# AltaRiscv register map
File version: 1.0
Registers are 32-bit, read-write, reset 0x0 unless marked. A register's access mark holds for its fields unless they carry their own. Offsets are from the block's base; lines under a group give offsets from that group; [hi:lo] are bit positions; {n}, {i} and the like mark numbered series; 'fields as' and 'values as' point back to an identical list; <NAME> marks a mode.

## Memory map
0x02000000 CLINT size 0x10000 — Core local interrupt controller
0x03000000 SYS size 0x1000 — System control
0x0C000000 PLIC size 0x400000 — Platform local interrupt controller
0x40000000 RTC size 0x80 — Real time clock
0x40001000 FLASH size 0x1000 — Flash controller
0x40010000 FCB0 size 0x1000 — FCB registers
0x40011000 WATCHDOG0 size 0x1000 — WATCHDOG registers
0x40012000 SPI0 size 0x100 — SPI registers
0x40013000 SPI1 size 0x100
0x40014000 GPIO0 size 0x1000 — GPIO registers
{0x40014000+0x1000*n} GPIO{n} size 0x1000 (n=1..9)
0x4001E000 TIMER0 size 0x1000 — TIMER registers
0x4001F000 TIMER1 size 0x1000
0x40020000 GPTIMER0 size 0x1000 — GPTIMER registers
0x40021000 GPTIMER1 size 0x1000
0x40022000 GPTIMER2 size 0x1000
0x40023000 GPTIMER3 size 0x1000
0x40024000 GPTIMER4 size 0x1000
0x40025000 UART0 size 0x1000 — UART registers
0x40026000 UART1 size 0x1000
0x40027000 UART2 size 0x1000
0x40028000 UART3 size 0x1000
0x40029000 UART4 size 0x1000
0x4002A000 CAN0 size 0x400 — CAN registers
0x4002B000 I2C0 size 0x100 — I2C registers
0x4002C000 I2C1 size 0x100
0x41000000 DMAC0 size 0x1000 — DMAC registers
0x41001000 USB0 size 0x200 — USB registers
0x41002000 CRC0 size 0x100 — CRC registers
0x41040000 MAC0 size 0x40000 — MAC registers

## CLINT — Core local interrupt controller
Base 0x02000000
0x00 msip — MSIP Bits
  [0] msip_0 — MSIP bit for Hart 0
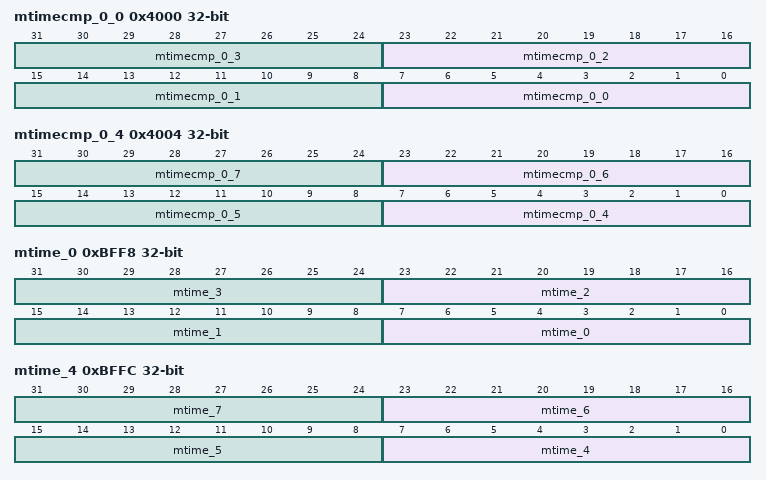
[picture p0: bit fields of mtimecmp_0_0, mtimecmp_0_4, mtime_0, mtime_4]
0x4000 mtimecmp_0_0 — MTIMECMP for hart 0
  [8n+7:8n] mtimecmp_0_{n} (n=0..3)
0x4004 mtimecmp_0_4 — MTIMECMP for hart 0
  [8n-25:8n-32] mtimecmp_0_{n} (n=4..7)
0xBFF8 mtime_0 — Timer Register
  [8n+7:8n] mtime_{n} (n=0..3)
0xBFFC mtime_4 — Timer Register
  [8n-25:8n-32] mtime_{n} (n=4..7)

## RTC — Real time clock
Base 0x40000000
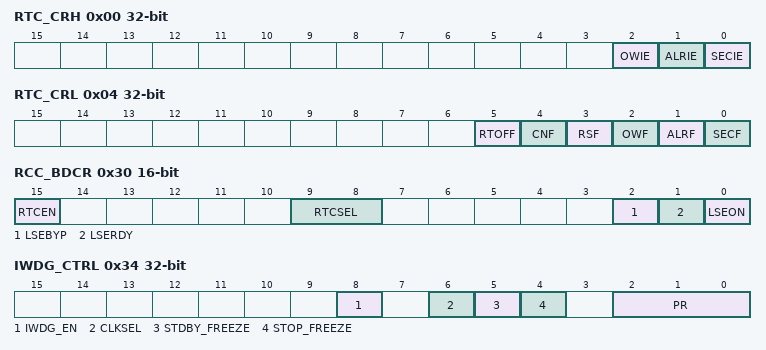
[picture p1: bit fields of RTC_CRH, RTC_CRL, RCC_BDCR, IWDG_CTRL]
0x00 RTC_CRH
  [2] OWIE — Overflow interrupt enable
  [1] ALRIE — Alarm interrupt enable
  [0] SECIE — Second interrupt enable
0x04 RTC_CRL access per field
  [5] RTOFF ro — RTC operation OFF
  [4] CNF rw — Configuration flag
  [3] RSF rw — Registers synchronized flag
  [2] OWF rw — Overflow flag
  [1] ALRF rw — Alarm flag
  [0] SECF rw — Second flag
0x08 RTC_PRLH — RTC prescaler load register high
  [3:0] RTC_PRLH
0x0C RTC_PRLL — RTC prescaler load register low
  [15:0] RTC_PRLL
0x10 RTC_DIVH — RTC prescaler divider register high
  [3:0] RTC_DIVH
0x14 RTC_DIVL — RTC prescaler divider register low
  [15:0] RTC_DIVL
0x18 RTC_CNTH — RTC counter register high
  [15:0] RTC_CNTH
0x1C RTC_CNTL — RTC counter register low
  [15:0] RTC_CNTL
0x20 RTC_ALRH — RTC alarm register high
  [15:0] RTC_ALRH
0x24 RTC_ALRL — RTC alarm register low
  [15:0] RTC_ALRL
0x28 RTC_RCYC — Read minimum cycle
  [3:0] RTC_RCYC
0x30 RCC_BDCR 16-bit — Backup domain control register
  [15] RTCEN — RTC enable
  [9:8] RTCSEL — RTC source selection
    0=No clock; 1=LSE; 2=LSI; 3=External
  [2] LSEBYP — Low speed external oscillator ready bypass
  [1] LSERDY — Low speed external oscillator ready
  [0] LSEON — Low speed external oscillator enable
0x32 RCC_BDRST 16-bit — Backup domain software reset
  [0] RCC_BDRST
0x34 IWDG_CTRL — Independent watchdog control
  [8] IWDG_EN — IWDG enable
  [6] CLKSEL — IWDG clock source selection in non-standby mode
    0=LSI; 1=LSE
  [5] STDBY_FREEZE — Freeze IWDG clock in standby mode
  [4] STOP_FREEZE — Freeze IWDG clock in stop mode
  [2:0] PR — Prescaler register
    0=Div 2; 1=Div 4; 2=Div 8; 3=Div 16; 4=Div 32; 5=Div 64; 6=Div 128; 7=Div 256
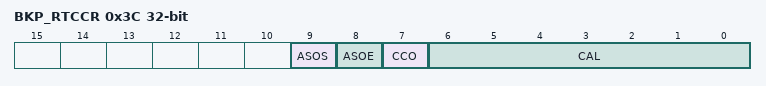
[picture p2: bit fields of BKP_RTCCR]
0x3C BKP_RTCCR — RTC clock calibration register
  [9] ASOS — Alarm or second output selection
    0=Alarm output; 1=Second output
  [8] ASOE — Alarm or second output enable
  [7] CCO — Calibration clock output
  [6:0] CAL — RTC calibration value
{0x40+4i} BKP_DR{i} (i=0..15) — Backup data register {i}
  [15:0] BKP_DR{i}
